# M440 register map
File version: 0.1
Registers are 32-bit, read-write, reset 0x0 unless marked. A register's access mark holds for its fields unless they carry their own. Offsets are from the block's base; [hi:lo] are bit positions; {n}, {i} and the like mark numbered series; 'fields as' and 'values as' point back to an identical list.

## DMACA — DMA Controller
Base 0x40000000
Same registers: DMACB 0x40001000, DMACC 0x40002000
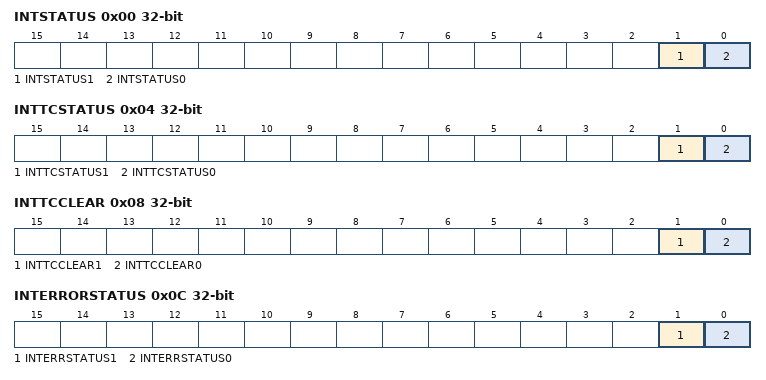
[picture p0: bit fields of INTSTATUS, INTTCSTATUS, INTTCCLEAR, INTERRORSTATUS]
0x00 INTSTATUS ro — DMAC Interrupt Status Register
  [1] INTSTATUS1, [0] INTSTATUS0
0x04 INTTCSTATUS ro — DMAC Interrupt Terminal Count Status Register
  [1] INTTCSTATUS1, [0] INTTCSTATUS0
0x08 INTTCCLEAR wo — DMAC Interrupt Terminal Count Clear Register
  [1] INTTCCLEAR1, [0] INTTCCLEAR0
0x0C INTERRORSTATUS ro — DMAC Interrupt Error Status Register
  [1] INTERRSTATUS1, [0] INTERRSTATUS0
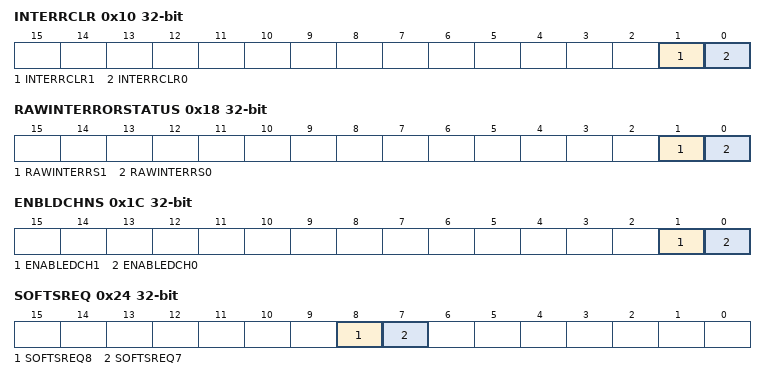
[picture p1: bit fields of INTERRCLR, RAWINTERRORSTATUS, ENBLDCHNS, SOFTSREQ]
0x10 INTERRCLR wo — DMAC Interrupt Error Clear Register
  [1] INTERRCLR1, [0] INTERRCLR0
0x14 RAWINTTCSTATUS ro — DMAC Raw Interrupt Terminal Count Status Register
  [0] RAMINTTCS0, [0] RAMINTTCS1
0x18 RAWINTERRORSTATUS ro — DMAC Raw Error Interrupt Status Register
  [1] RAWINTERRS1, [0] RAWINTERRS0
0x1C ENBLDCHNS ro — DMAC Enabled Channel Register
  [1] ENABLEDCH1, [0] ENABLEDCH0
0x20 SOFTBREQ — DMAC Software Burst Request Register
  [15:0] SOFTBREQ
0x24 SOFTSREQ — DMAC Software Single Request Register
  [8] SOFTSREQ8, [7] SOFTSREQ7
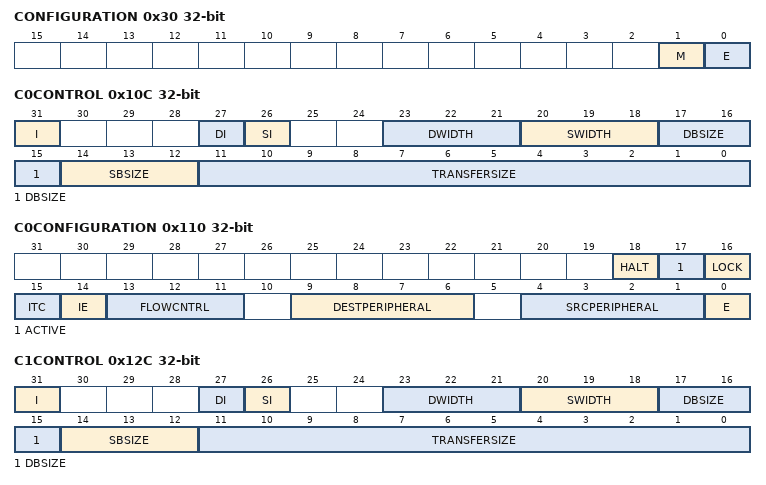
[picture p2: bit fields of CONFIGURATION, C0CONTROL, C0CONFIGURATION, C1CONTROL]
0x30 CONFIGURATION — DMAC Configuration Register
  [1] M, [0] E
0x100 C0SRCADDR — DMAC Channel 0 Source Address Register
  [31:0] SRCADDR
0x104 C0DESTADDR — DMAC Channel 0 Destination Address Register
  [31:0] DESTADDR
0x108 C0LLI — DMAC Channel 0 Linked List Item Register
  [31:2] LLI
0x10C C0CONTROL — DMAC Channel 0 Control Register
  [31] I, [27] DI, [26] SI, [23:21] DWIDTH, [20:18] SWIDTH, [17:15] DBSIZE, [14:12] SBSIZE, [11:0] TRANSFERSIZE
0x110 C0CONFIGURATION (reset mask 0x7FBDE) — DMAC Channel 0 Configuration Register
  [18] HALT, [17] ACTIVE ro, [16] LOCK, [15] ITC, [14] IE, [13:11] FLOWCNTRL, [9:6] DESTPERIPHERAL, [4:1] SRCPERIPHERAL, [0] E
0x120 C1SRCADDR — DMAC Channel 1 Source Address Register
  [31:0] SRCADDR
0x124 C1DESTADDR — DMAC Channel 1 Destination Address Register
  [31:0] DESTADDR
0x128 C1LLI — DMAC Channel 1 Linked List Item Register
  [31:2] LLI
0x12C C1CONTROL — DMAC Channel 1 Control Register
  fields as C0CONTROL
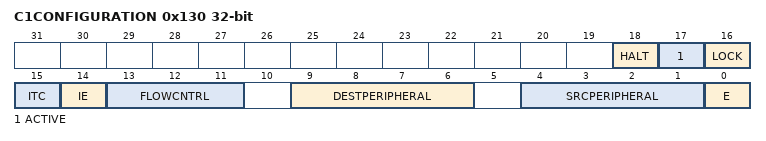
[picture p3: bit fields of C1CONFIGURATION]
0x130 C1CONFIGURATION (reset mask 0x7FBDE) — DMAC Channel 1 Configuration Register
  fields as C0CONFIGURATION

## DMACNone — DMA Controller
Base 0x4405F000
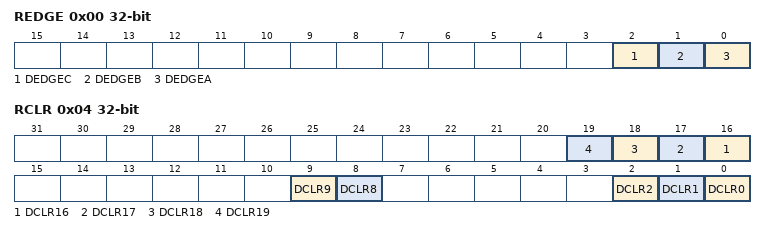
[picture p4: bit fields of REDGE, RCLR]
0x00 REDGE — DMAC Request Edge Setting Register
  [2] DEDGEC, [1] DEDGEB, [0] DEDGEA
0x04 RCLR wo — DMAC Request Clear Register
  [n] DCLR{n} (n=16..19), [9] DCLR9, [8] DCLR8, [2] DCLR2 ro, [1] DCLR1, [0] DCLR0

## PSC — Programmable Servo Controller
Base 0x40018000
0x00 UA0 — Accumulator
0x04 UM0 — Multiplier Register
0x08 UM1 — Shift Count Register
0x0C UL0 — Upper Limit Value Register
0x10 UL1 — Lower Limit Value Register
0x14 UR0 — Add Sub Value Register 0
0x18 UR1 — Add Sub Value Register 1
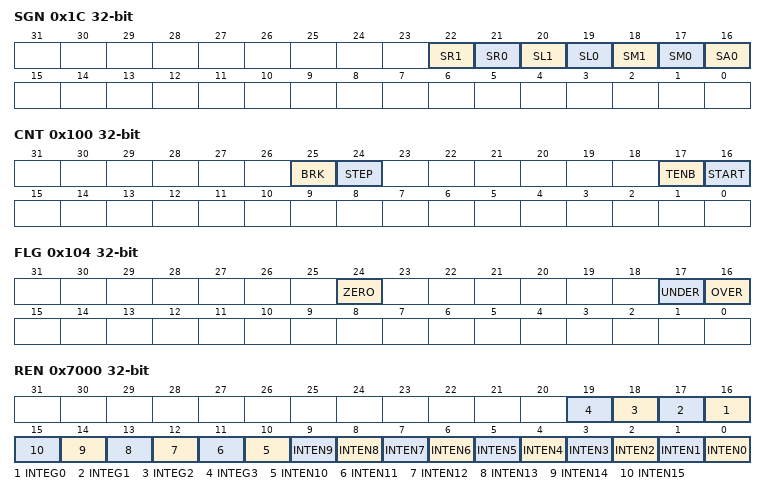
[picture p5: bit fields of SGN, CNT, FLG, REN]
0x1C SGN — Arithmetic Parameter with Signed Register
  [22] SR1, [21] SR0, [20] SL1, [19] SL0, [18] SM1, [17] SM0, [16] SA0
{0x20+4i} AP{i} (i=0..3) — Address Pointer {i}
0x30 BR0 — Break Pointer
0x34 PG0 — Program Counter
0x38 VG0 — Repeat Processing Vector Pointer
0x100 CNT — Control Register
  [25] BRK, [24] STEP, [17] TENB ro, [16] START
0x104 FLG — Flag Register
  [24] ZERO, [17] UNDER, [16] OVER
0x7000 REN — Run Trigger Enable Register
  [n+16] INTEG{n} (n=0..3), [n] INTEN{n} (n=0..15)
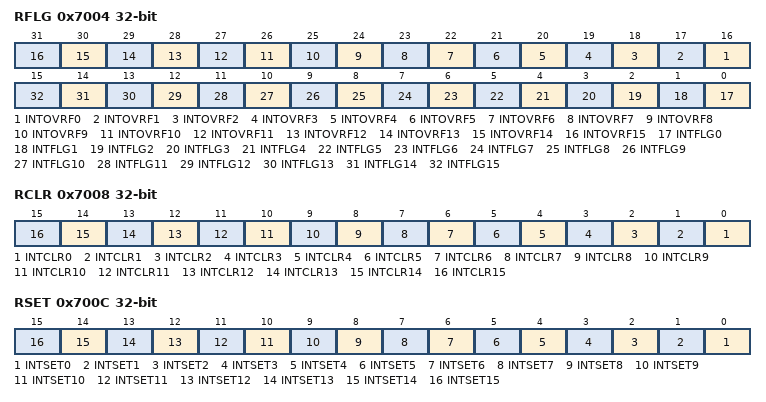
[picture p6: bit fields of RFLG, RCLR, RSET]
0x7004 RFLG ro — Run Trigger Flag Register
  [n+16] INTOVRF{n} (n=0..15), [n] INTFLG{n} (n=0..15)
0x7008 RCLR wo — Run Trigger Clear Register
  [n] INTCLR{n} (n=0..15)
0x700C RSET wo — Run Trigger Clear Register
  [n] INTSET{n} (n=0..15)
0x7100 PTOUT — Port Output Enable Register for PSC
  [7:0] PSCPTO
0x7104 PTCR — Port Control Register for PSC
  [7:0] PSCPTC
0x7108 PTIN ro — Port Input Enable Register for PSC
  [7:0] PSCPTI

## SSP — Synchronous Serial Port
Base 0x40040000
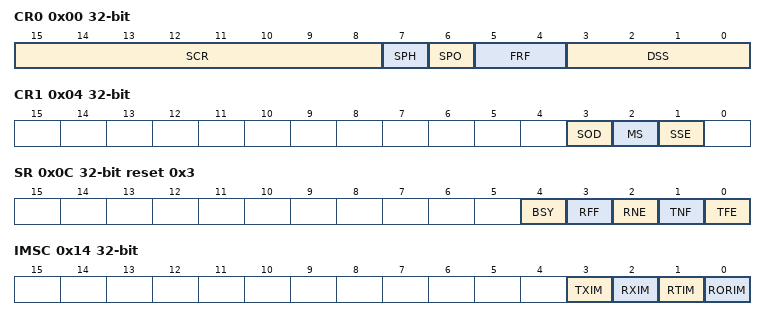
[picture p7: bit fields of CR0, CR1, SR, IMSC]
0x00 CR0 — Control Register 0
  [15:8] SCR, [7] SPH, [6] SPO, [5:4] FRF, [3:0] DSS
0x04 CR1 — Control Register 1
  [3] SOD, [2] MS, [1] SSE
0x08 DR — Data Register
  [15:0] DATA
0x0C SR ro reset 0x3 — Status Register
  [4] BSY, [3] RFF, [2] RNE, [1] TNF, [0] TFE
0x10 CPSR — Clock Prescale Register
  [7:0] CPSDVSR
0x14 IMSC — Interrupt Mask Set And Clear Register
  [3] TXIM, [2] RXIM, [1] RTIM, [0] RORIM
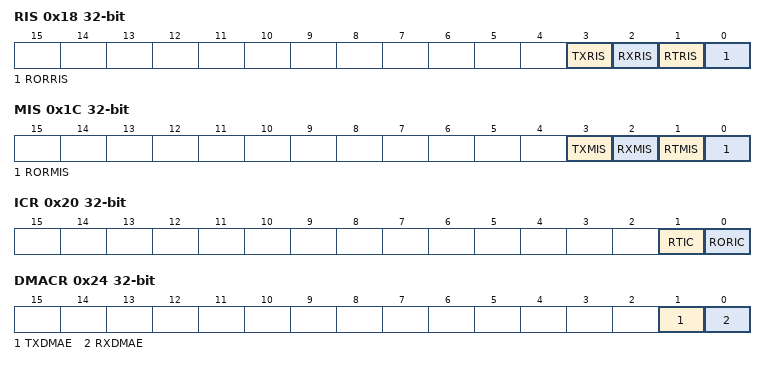
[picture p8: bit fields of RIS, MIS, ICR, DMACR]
0x18 RIS ro — Raw Interrupt Status Register
  [3] TXRIS, [2] RXRIS, [1] RTRIS, [0] RORRIS
0x1C MIS ro — Masked Interrupt Status Register
  [3] TXMIS, [2] RXMIS, [1] RTMIS, [0] RORMIS
0x20 ICR wo reset not defined — Interrupt Clear Register
  [1] RTIC, [0] RORIC
0x24 DMACR — DMA Control Register
  [1] TXDMAE, [0] RXDMAE
